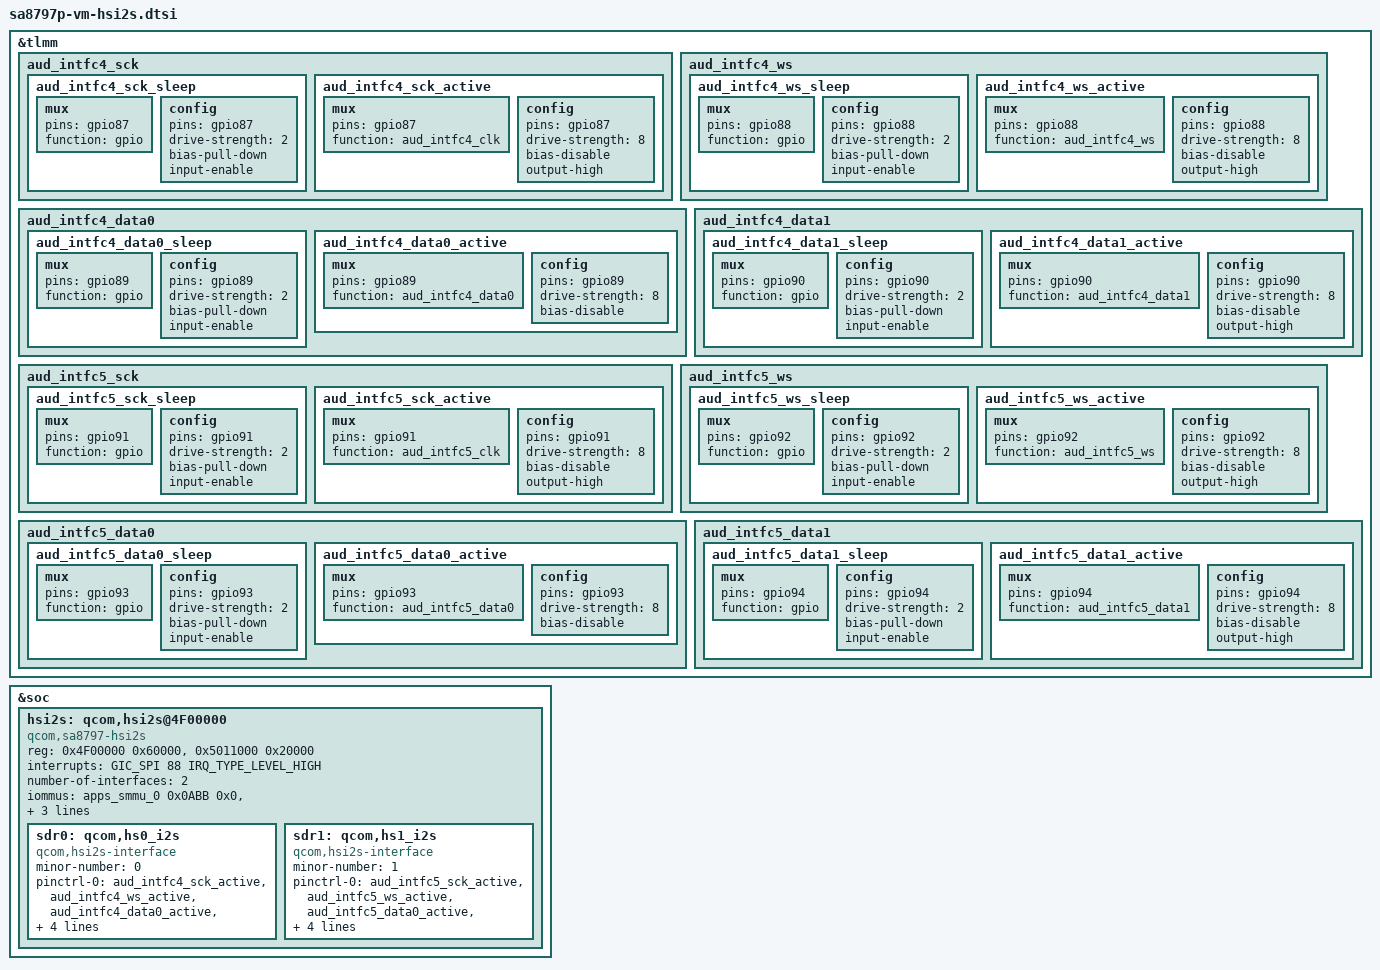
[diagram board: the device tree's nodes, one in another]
// SPDX-License-Identifier: BSD-3-Clause

/*
 * Copyright (c) Qualcomm Technologies, Inc. and/or its subsidiaries.
 */

&tlmm {
	aud_intfc4_sck {
		aud_intfc4_sck_sleep: aud_intfc4_sck_sleep {
			mux {
				pins = "gpio87";
				function = "gpio";
			};

			config {
				pins = "gpio87";
				drive-strength = <2>;   /* 2 mA */
				bias-pull-down;         /* PULL DOWN */
				input-enable;
			};
		};

		aud_intfc4_sck_active: aud_intfc4_sck_active {
			mux {
				pins = "gpio87";
				function = "aud_intfc4_clk";
			};

			config {
				pins = "gpio87";
				drive-strength = <8>;   /* 8 mA */
				bias-disable;           /* NO PULL */
				output-high;
			};
		};
	};

	aud_intfc4_ws {
		aud_intfc4_ws_sleep: aud_intfc4_ws_sleep {
			mux {
				pins = "gpio88";
				function = "gpio";
			};

			config {
				pins = "gpio88";
				drive-strength = <2>;   /* 2 mA */
				bias-pull-down;         /* PULL DOWN */
				input-enable;
			};
		};

		aud_intfc4_ws_active: aud_intfc4_ws_active {
			mux {
				pins = "gpio88";
				function = "aud_intfc4_ws";
			};

			config {
				pins = "gpio88";
				drive-strength = <8>;   /* 8 mA */
				bias-disable;           /* NO PULL */
				output-high;
			};
		};
	};

	aud_intfc4_data0 {
		aud_intfc4_data0_sleep: aud_intfc4_data0_sleep {
			mux {
				pins = "gpio89";
				function = "gpio";
			};

			config {
				pins = "gpio89";
				drive-strength = <2>;   /* 2 mA */
				bias-pull-down;         /* PULL DOWN */
				input-enable;
			};
		};

		aud_intfc4_data0_active: aud_intfc4_data0_active {
			mux {
				pins = "gpio89";
				function = "aud_intfc4_data0";
			};

			config {
				pins = "gpio89";
				drive-strength = <8>;   /* 8 mA */
				bias-disable;           /* NO PULL */
			};
		};
	};

	aud_intfc4_data1 {
		aud_intfc4_data1_sleep: aud_intfc4_data1_sleep {
			mux {
				pins = "gpio90";
				function = "gpio";
			};

			config {
				pins = "gpio90";
				drive-strength = <2>;   /* 2 mA */
				bias-pull-down;         /* PULL DOWN */
				input-enable;
			};
		};

		aud_intfc4_data1_active: aud_intfc4_data1_active {
			mux {
				pins = "gpio90";
				function = "aud_intfc4_data1";
			};

			config {
				pins = "gpio90";
				drive-strength = <8>;   /* 8 mA */
				bias-disable;           /* NO PULL */
				output-high;
			};
		};
	};

	aud_intfc5_sck {
		aud_intfc5_sck_sleep: aud_intfc5_sck_sleep {
			mux {
				pins = "gpio91";
				function = "gpio";
			};

			config {
				pins = "gpio91";
				drive-strength = <2>;   /* 2 mA */
				bias-pull-down;         /* PULL DOWN */
				input-enable;
			};
		};

		aud_intfc5_sck_active: aud_intfc5_sck_active {
			mux {
				pins = "gpio91";
				function = "aud_intfc5_clk";
			};

			config {
				pins = "gpio91";
				drive-strength = <8>;   /* 8 mA */
				bias-disable;           /* NO PULL */
				output-high;
			};
		};
	};

	aud_intfc5_ws {
		aud_intfc5_ws_sleep: aud_intfc5_ws_sleep {
			mux {
				pins = "gpio92";
				function = "gpio";
			};

			config {
				pins = "gpio92";
				drive-strength = <2>;   /* 2 mA */
				bias-pull-down;         /* PULL DOWN */
				input-enable;
			};
		};

		aud_intfc5_ws_active: aud_intfc5_ws_active {
			mux {
				pins = "gpio92";
				function = "aud_intfc5_ws";
			};

			config {
				pins = "gpio92";
				drive-strength = <8>;   /* 8 mA */
				bias-disable;           /* NO PULL */
				output-high;
			};
		};
	};

	aud_intfc5_data0 {
		aud_intfc5_data0_sleep: aud_intfc5_data0_sleep {
			mux {
				pins = "gpio93";
				function = "gpio";
			};

			config {
				pins = "gpio93";
				drive-strength = <2>;   /* 2 mA */
				bias-pull-down;         /* PULL DOWN */
				input-enable;
			};
		};

		aud_intfc5_data0_active: aud_intfc5_data0_active {
			mux {
				pins = "gpio93";
				function = "aud_intfc5_data0";
			};

			config {
				pins = "gpio93";
				drive-strength = <8>;   /* 8 mA */
				bias-disable;           /* NO PULL */
			};
		};
	};

	aud_intfc5_data1 {
		aud_intfc5_data1_sleep: aud_intfc5_data1_sleep {
			mux {
				pins = "gpio94";
				function = "gpio";
			};

			config {
				pins = "gpio94";
				drive-strength = <2>;   /* 2 mA */
				bias-pull-down;         /* PULL DOWN */
				input-enable;
			};
		};

		aud_intfc5_data1_active: aud_intfc5_data1_active {
			mux {
				pins = "gpio94";
				function = "aud_intfc5_data1";
			};

			config {
				pins = "gpio94";
				drive-strength = <8>;   /* 8 mA */
				bias-disable;           /* NO PULL */
				output-high;
			};
		};
	};
};

&soc {
	hsi2s: qcom,hsi2s@4F00000 {
		compatible = "qcom,sa8797-hsi2s", "qcom,hsi2s";
		reg = <0x4F00000 0x60000>, <0x5011000 0x20000>;
		interrupts = <GIC_SPI 88 IRQ_TYPE_LEVEL_HIGH>;
		number-of-interfaces = <2>;
		iommus = <&apps_smmu_0 0x0ABB 0x0>,
			<&apps_smmu_0 0x0ABC 0x1>;
		qcom,iommu-dma-addr-pool = <0x0 0xFFFFFFFF>;
		dma-coherent;

		sdr0: qcom,hs0_i2s {
			compatible = "qcom,hsi2s-interface";
			minor-number = <0>;
			pinctrl-names = "default", "sleep";
			pinctrl-0 = <&aud_intfc4_sck_active
				     &aud_intfc4_ws_active
				     &aud_intfc4_data0_active
				     &aud_intfc4_data1_active>;
			pinctrl-1 = <&aud_intfc4_sck_sleep
				     &aud_intfc4_ws_sleep
				     &aud_intfc4_data0_sleep
				     &aud_intfc4_data1_sleep>;
		};

		sdr1: qcom,hs1_i2s {
			compatible = "qcom,hsi2s-interface";
			minor-number = <1>;
			pinctrl-names = "default", "sleep";
			pinctrl-0 = <&aud_intfc5_sck_active
				     &aud_intfc5_ws_active
				     &aud_intfc5_data0_active
				     &aud_intfc5_data1_active>;
			pinctrl-1 = <&aud_intfc5_sck_sleep
				     &aud_intfc5_ws_sleep
				     &aud_intfc5_data0_sleep
				     &aud_intfc5_data1_sleep>;
		};
	};
};
